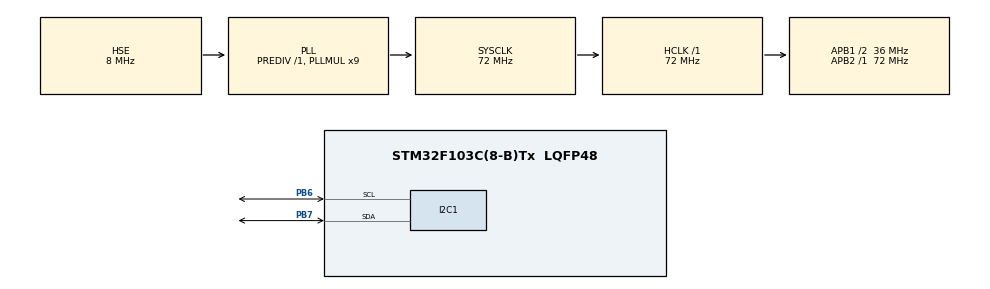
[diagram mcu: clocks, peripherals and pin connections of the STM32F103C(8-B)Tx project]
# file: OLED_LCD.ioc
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Mcu.Family=STM32F1
RCC.PLLSourceVirtual=RCC_PLLSOURCE_HSE
PD1-OSC_OUT.Mode=HSE-External-Oscillator
PD0-OSC_IN.Signal=RCC_OSC_IN
RCC.APB1CLKDivider=RCC_HCLK_DIV2
RCC.SYSCLKSource=RCC_SYSCLKSOURCE_PLLCLK
ProjectManager.StackSize=0x400
PD1-OSC_OUT.Signal=RCC_OSC_OUT
PA13.Signal=SYS_JTMS-SWDIO
ProjectManager.TargetToolchain=MDK-ARM V5
I2C1.I2C_Mode=I2C_Fast
RCC.HCLKFreq_Value=72000000
RCC.APB2TimFreq_Value=72000000
PB6.Signal=I2C1_SCL
PB6.Mode=I2C
RCC.USBFreq_Value=72000000
RCC.AHBFreq_Value=72000000
PD0-OSC_IN.Mode=HSE-External-Oscillator
board=custom
RCC.PLLMUL=RCC_PLL_MUL9
RCC.APB2Freq_Value=72000000
PA14.Mode=Serial_Wire
PB7.Signal=I2C1_SDA
PA13.Mode=Serial_Wire
Mcu.Name=STM32F103C(8-B)Tx
RCC.SYSCLKFreq_VALUE=72000000
Mcu.Package=LQFP48
PB7.Mode=I2C
PA14.Signal=SYS_JTCK-SWCLK
ProjectManager.HeapSize=0x200
NVIC.PriorityGroup=NVIC_PRIORITYGROUP_4
RCC.APB1TimFreq_Value=72000000
RCC.APB1Freq_Value=36000000

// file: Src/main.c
/* USER CODE BEGIN Header */
/**
  ******************************************************************************
  * @file           : main.c
  * @brief          : Main program body
  ******************************************************************************
  * @attention
  *
  * <h2><center>&copy; Copyright (c) 2020 STMicroelectronics.
  * All rights reserved.</center></h2>
  *
  * This software component is licensed by ST under BSD 3-Clause license,
  * the "License"; You may not use this file except in compliance with the
  * License. You may obtain a copy of the License at:
  *                        opensource.org/licenses/BSD-3-Clause
  *
  ******************************************************************************
  */
/* USER CODE END Header */

#include "main.h"

/* USER CODE BEGIN Includes */
//#include "ssd1306.h"
#include "OLED_LCD_SSD1306.h"
#include "test.h"
#include "logo2.h"
#include "1.h"
#include "2.h"
#include "3.h"
#include "4.h"
#include "5.h"
#include "6.h"
#include "7.h"
#include "8.h"
#include "9.h"

#define OLED_I2C_PORT hi2c1
/* USER CODE END Includes */

I2C_HandleTypeDef hi2c1;

/* USER CODE BEGIN PV */
//SSD1306_Name SH1106;
SSD1306_Name SSD1306;
/* USER CODE END PV */

void SystemClock_Config(void);
static void MX_GPIO_Init(void);
static void MX_I2C1_Init(void);

int main(void)
{

  /* MCU Configuration--------------------------------------------------------*/

  /* Reset of all peripherals, Initializes the Flash interface and the Systick. */
  HAL_Init();

  /* Configure the system clock */
  SystemClock_Config();

  /* Initialize all configured peripherals */
  MX_GPIO_Init();
  MX_I2C1_Init();
  /* USER CODE BEGIN 2 */
	SSD1306_Init(&SSD1306, &hi2c1);

  /* USER CODE END 2 */

  /* Infinite loop */
  while (1)
  {
    /* USER CODE BEGIN 3 */
		//display shape
		TestLines(1);
    HAL_Delay (1000);
    TestRectangles(1);
    HAL_Delay (1000);
    TestFilledRectangles(1);
    HAL_Delay (1000);
    TestCircles(6,1);
    HAL_Delay (1000);
    TestFilledCircles(6, 1);
    TestTriangles(1);
		HAL_Delay (1000);

		//display text
		SSD1306_Clear(&SSD1306);
		SSD1306_GotoXY (&SSD1306, 1,1);
    SSD1306_Puts (&SSD1306, "KHUE NGUYEN", &Font_11x18, SSD1306_COLOR_WHITE);
    SSD1306_GotoXY (&SSD1306, 10, 30);
    SSD1306_Puts (&SSD1306,"  CREATOR", &Font_11x18, SSD1306_COLOR_WHITE);
    SSD1306_UpdateScreen(&SSD1306); //display
    HAL_Delay (2000);

		//display image
		SSD1306_Clear(&SSD1306);
    SSD1306_DrawBitmap(&SSD1306, 0,0,gImage_logo2, 132, 64, SSD1306_COLOR_WHITE);
    SSD1306_UpdateScreen(&SSD1306);
    HAL_Delay(5000);

		// scroll image
    SSD1306_ScrollRight(&SSD1306, 0x00, 0x0f);    // scroll entire screen right
    HAL_Delay (2000);
    SSD1306_ScrollLeft(&SSD1306, 0x00, 0x0f);  // scroll entire screen left
    HAL_Delay (2000);
    SSD1306_Scrolldiagright(&SSD1306, 0x00, 0x0f);  // scroll entire screen diagonal right
    HAL_Delay (2000);
    SSD1306_Scrolldiagleft(&SSD1306, 0x00, 0x0f);  // scroll entire screen diagonal left
    HAL_Delay (2000);
    SSD1306_Stopscroll(&SSD1306);   // stop scrolling. If not done, screen will keep on scrolling
    SSD1306_InvertDisplay(&SSD1306, 1);   // invert the display
    HAL_Delay(2000);
    SSD1306_InvertDisplay(&SSD1306, 0);  // normalize the display
    HAL_Delay(2000);

		//display animation
		uint8_t loop = 5;
		while(loop--)
		{
			SSD1306_Clear(&SSD1306);
			SSD1306_DrawBitmap(&SSD1306,0,0,gImage_1,132,64,SSD1306_COLOR_WHITE);
			SSD1306_UpdateScreen(&SSD1306);
			SSD1306_Clear(&SSD1306);
			SSD1306_DrawBitmap(&SSD1306,0,0,gImage_2,132,64,SSD1306_COLOR_WHITE);
			SSD1306_UpdateScreen(&SSD1306);
			SSD1306_Clear(&SSD1306);
			SSD1306_DrawBitmap(&SSD1306,0,0,gImage_3,132,64,SSD1306_COLOR_WHITE);
			SSD1306_UpdateScreen(&SSD1306);
			SSD1306_Clear(&SSD1306);
			SSD1306_DrawBitmap(&SSD1306,0,0,gImage_4,132,64,SSD1306_COLOR_WHITE);
			SSD1306_UpdateScreen(&SSD1306);
			SSD1306_Clear(&SSD1306);
			SSD1306_DrawBitmap(&SSD1306,0,0,gImage_5,132,64,SSD1306_COLOR_WHITE);
			SSD1306_UpdateScreen(&SSD1306);
			SSD1306_Clear(&SSD1306);
			SSD1306_DrawBitmap(&SSD1306,0,0,gImage_6,132,64,SSD1306_COLOR_WHITE);
			SSD1306_UpdateScreen(&SSD1306);
			SSD1306_Clear(&SSD1306);
			SSD1306_DrawBitmap(&SSD1306,0,0,gImage_7,132,64,SSD1306_COLOR_WHITE);
			SSD1306_UpdateScreen(&SSD1306);
			SSD1306_Clear(&SSD1306);
			SSD1306_DrawBitmap(&SSD1306, 0,0,gImage_8,132,64,SSD1306_COLOR_WHITE);
			SSD1306_UpdateScreen(&SSD1306);
			SSD1306_Clear(&SSD1306);
			SSD1306_DrawBitmap(&SSD1306,0,0,gImage_9,132,64,SSD1306_COLOR_WHITE);
			SSD1306_UpdateScreen(&SSD1306);
		}
	}
  /* USER CODE END 3 */
}

void SystemClock_Config(void)
{
  RCC_OscInitTypeDef RCC_OscInitStruct = {0};
  RCC_ClkInitTypeDef RCC_ClkInitStruct = {0};

  /** Initializes the CPU, AHB and APB busses clocks
  */
  RCC_OscInitStruct.OscillatorType = RCC_OSCILLATORTYPE_HSE;
  RCC_OscInitStruct.HSEState = RCC_HSE_ON;
  RCC_OscInitStruct.HSEPredivValue = RCC_HSE_PREDIV_DIV1;
  RCC_OscInitStruct.HSIState = RCC_HSI_ON;
  RCC_OscInitStruct.PLL.PLLState = RCC_PLL_ON;
  RCC_OscInitStruct.PLL.PLLSource = RCC_PLLSOURCE_HSE;
  RCC_OscInitStruct.PLL.PLLMUL = RCC_PLL_MUL9;
  if (HAL_RCC_OscConfig(&RCC_OscInitStruct) != HAL_OK)
  {
    Error_Handler();
  }
  /** Initializes the CPU, AHB and APB busses clocks
  */
  RCC_ClkInitStruct.ClockType = RCC_CLOCKTYPE_HCLK|RCC_CLOCKTYPE_SYSCLK
                              |RCC_CLOCKTYPE_PCLK1|RCC_CLOCKTYPE_PCLK2;
  RCC_ClkInitStruct.SYSCLKSource = RCC_SYSCLKSOURCE_PLLCLK;
  RCC_ClkInitStruct.AHBCLKDivider = RCC_SYSCLK_DIV1;
  RCC_ClkInitStruct.APB1CLKDivider = RCC_HCLK_DIV2;
  RCC_ClkInitStruct.APB2CLKDivider = RCC_HCLK_DIV1;

  if (HAL_RCC_ClockConfig(&RCC_ClkInitStruct, FLASH_LATENCY_2) != HAL_OK)
  {
    Error_Handler();
  }
}

static void MX_I2C1_Init(void)
{

  hi2c1.Instance = I2C1;
  hi2c1.Init.ClockSpeed = 400000;
  hi2c1.Init.DutyCycle = I2C_DUTYCYCLE_2;
  hi2c1.Init.OwnAddress1 = 0;
  hi2c1.Init.AddressingMode = I2C_ADDRESSINGMODE_7BIT;
  hi2c1.Init.DualAddressMode = I2C_DUALADDRESS_DISABLE;
  hi2c1.Init.OwnAddress2 = 0;
  hi2c1.Init.GeneralCallMode = I2C_GENERALCALL_DISABLE;
  hi2c1.Init.NoStretchMode = I2C_NOSTRETCH_DISABLE;
  if (HAL_I2C_Init(&hi2c1) != HAL_OK)
  {
    Error_Handler();
  }

}

static void MX_GPIO_Init(void)
{

  /* GPIO Ports Clock Enable */
  __HAL_RCC_GPIOD_CLK_ENABLE();
  __HAL_RCC_GPIOA_CLK_ENABLE();
  __HAL_RCC_GPIOB_CLK_ENABLE();

}

void Error_Handler(void)
{
}

/************************ (C) COPYRIGHT STMicroelectronics *****END OF FILE****/
